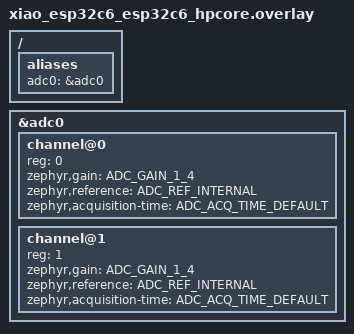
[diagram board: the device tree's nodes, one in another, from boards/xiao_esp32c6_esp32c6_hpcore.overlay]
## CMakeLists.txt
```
# SPDX-FileCopyrightText: 2026 Henrique Freire <hfreire10@hotmail.com>

# SPDX-License-Identifier: MIT

cmake_minimum_required(VERSION 3.20.0)

list(APPEND EXTRA_ZEPHYR_MODULES ${CMAKE_CURRENT_LIST_DIR}/../../modules/wifi_sensing)

find_package(Zephyr REQUIRED HINTS $ENV{ZEPHYR_BASE})
project(collector)

target_sources(app PRIVATE
  src/csi.c
  src/main.c
  # src/sensor.c
)
target_include_directories(app PRIVATE include)
```

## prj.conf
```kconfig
# SPDX-FileCopyrightText: 2026 Henrique Freire <hfreire10@hotmail.com>

# SPDX-License-Identifier: MIT

# Debug
CONFIG_LOG=y
CONFIG_THREAD_NAME=y
CONFIG_STACK_CANARIES=y
CONFIG_STACK_SENTINEL=y
CONFIG_LOG_PROCESS_THREAD_STACK_SIZE=1024

# General
CONFIG_ADC=y
CONFIG_FPU=y
CONFIG_GPIO=y
CONFIG_FLASH=y
CONFIG_EVENTS=y
CONFIG_FLASH_MAP=y
CONFIG_STREAM_FLASH=y
CONFIG_MAIN_STACK_SIZE=4096
CONFIG_HEAP_MEM_POOL_SIZE=102400

# PM
#CONFIG_PM=y
#CONFIG_PM_DEVICE=y

# Networking
CONFIG_NET_UDP=y
CONFIG_NET_IPV4=y
CONFIG_POSIX_API=y
CONFIG_NETWORKING=y
CONFIG_NET_DHCPV4=y
CONFIG_NET_SOCKETS=y

# Try static ESP32 Wi-Fi TX buffers
CONFIG_NET_MAX_CONTEXTS=4
CONFIG_NET_PKT_TX_COUNT=16
CONFIG_NET_BUF_TX_COUNT=48
CONFIG_NET_BUF_DATA_SIZE=512

## WiFi
CONFIG_WIFI=y
CONFIG_WIFI_ESP32=y
CONFIG_NET_L2_WIFI_MGMT=y
CONFIG_WIFI_USAGE_MODE_STA=y
CONFIG_ESP32_WIFI_IRAM_OPT=y
CONFIG_ESP32_WIFI_RX_IRAM_OPT=y
CONFIG_ESP32_WIFI_CSI_ENABLED=y
CONFIG_ESP32_WIFI_STA_RECONNECT=y
```

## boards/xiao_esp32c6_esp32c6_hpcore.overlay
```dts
// SPDX-FileCopyrightText: 2026 Henrique Freire <hfreire10@hotmail.com>

// SPDX-License-Identifier: MIT

/ {
    aliases {
        adc0 = &adc0;
    };
};

&adc0 {
    status = "okay";

    #address-cells = <1>;
	#size-cells = <0>;

    channel@0 {
        reg = <0>;
        zephyr,gain = "ADC_GAIN_1_4";
        zephyr,reference = "ADC_REF_INTERNAL";
        zephyr,acquisition-time = <ADC_ACQ_TIME_DEFAULT>;
    };

    channel@1 {
        reg = <1>;
        zephyr,gain = "ADC_GAIN_1_4";
        zephyr,reference = "ADC_REF_INTERNAL";
        zephyr,acquisition-time = <ADC_ACQ_TIME_DEFAULT>;
    };
};
```

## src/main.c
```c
// SPDX-FileCopyrightText: 2026 Henrique Freire <hfreire10@hotmail.com>

// SPDX-License-Identifier: MIT

#include <zephyr/device.h>
#include <zephyr/devicetree.h>
#include <zephyr/drivers/adc.h>
#include <zephyr/drivers/gpio.h>
#include <zephyr/kernel.h>
#include <zephyr/logging/log.h>
#include <zephyr/net/net_if.h>
#include <zephyr/net/socket.h>
#include <zephyr/net/wifi_mgmt.h>
#include <zephyr/posix/arpa/inet.h>
#include <zephyr/posix/sys/socket.h>
#include <zephyr/posix/unistd.h>

#include <wifi_sensing.h>

#include "collector.h"

LOG_MODULE_REGISTER(collector);

// clang-format off
const struct device *g_adc                = DEVICE_DT_GET(ADC_NODE);
const struct adc_channel_cfg g_adc_cfgs[ADC_CHANNEL_COUNT] = {
    DT_FOREACH_CHILD_SEP(ADC_NODE, ADC_CHANNEL_CFG_DT, (,))
};
// clang-format on

struct in_addr g_ap_addr;
uint8_t g_mac_addr[MAC_ADDR_LEN];

K_SEM_DEFINE(g_sensing_sem, 0, 1);

int udp_socket_open(struct in_addr dest_addr) {
  int sock;
  char ip_str[INET_ADDRSTRLEN];

  struct sockaddr_in server_addr = {
      .sin_family = AF_INET,
      .sin_port   = htons(CONFIG_UDP_PORT),
      .sin_addr   = dest_addr,
  };

  sock = socket(AF_INET, SOCK_DGRAM, IPPROTO_UDP);
  if (sock < 0) {
    LOG_ERR("Failed to create UDP socket: %d", errno);
    return sock;
  }

  if (connect(sock, (struct sockaddr *)&server_addr, sizeof(server_addr)) < 0) {
    LOG_ERR("Failed to connect UDP socket: %d", errno);
    close(sock);
    return -1;
  }

  inet_ntop(AF_INET, &dest_addr, ip_str, sizeof(ip_str));
  LOG_INF("UDP socket registered to %s:%d", ip_str, CONFIG_UDP_PORT);

  return sock;
}

static void adc_init(void) {
  if (!device_is_ready(g_adc)) {
    LOG_ERR("ADC device controller is not ready\n");
  }

  for (size_t i = 0; i < ADC_CHANNEL_COUNT; i++) {
    int err = adc_channel_setup(g_adc, &g_adc_cfgs[i]);

    if (err < 0) {
      LOG_ERR("Could not setup channel #%d: %d\n", g_adc_cfgs[i].channel_id, err);
    }
  }

  // Only setup first ADC sensor (for now)
  g_adc_sequence.channels |= BIT(g_adc_cfgs[0].channel_id);
}

int main(void) {
  LOG_INF("Starting Wi-Fi sensor");

  // Enable environmental sensors and integrated (communication) antenna
  adc_init();
  enable_antenna(INT_ANT);

  net_register(&g_ap_addr);

  wifi_csi_init();
  ap_connect(g_mac_addr);

  return 0;
}
```

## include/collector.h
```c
// SPDX-FileCopyrightText: 2026 Henrique Freire <hfreire10@hotmail.com>

// SPDX-License-Identifier: MIT

#pragma once

#include <stdint.h>

#include <zephyr/devicetree.h>
#include <zephyr/drivers/adc.h>
#include <zephyr/drivers/gpio.h>
#include <zephyr/kernel.h>
#include <zephyr/logging/log.h>

#include <wifi_sensing.h>

#define PACKED __attribute__((packed))

#define ADC_RES           12
#define ADC_NODE          DT_ALIAS(adc0)
#define ADC_CHANNEL_COUNT DT_CHILD_NUM(ADC_NODE)

#define RF_SWITCH_NODE DT_NODELABEL(rf_switch)

typedef enum {
  INT_ANT,
  EXT_ANT,
} antenna_e;

BUILD_ASSERT(DT_NODE_HAS_STATUS_OKAY(ADC_NODE), "ADC controller disabled");

static const struct gpio_dt_spec s_ant_sel = GPIO_DT_SPEC_GET(RF_SWITCH_NODE, select_gpios);

extern const struct device *g_adc;
extern const struct adc_channel_cfg g_adc_cfgs[ADC_CHANNEL_COUNT];

extern struct in_addr g_ap_addr;
extern struct k_sem g_sensing_sem;
extern uint8_t g_mac_addr[MAC_ADDR_LEN];
extern struct adc_sequence g_adc_sequence;

void wifi_csi_init(void);
int udp_socket_open(struct in_addr dest_addr);

static inline void enable_antenna(antenna_e antenna) {
  LOG_MODULE_DECLARE(collector);

  if (!gpio_is_ready_dt(&s_ant_sel)) {
    LOG_ERR("Antenna select GPIO not ready");
    return;
  }

  gpio_pin_set_dt(&s_ant_sel, antenna);
}
```

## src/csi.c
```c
// SPDX-FileCopyrightText: 2026 Henrique Freire <hfreire10@hotmail.com>

// SPDX-License-Identifier: MIT

#include <stdint.h>

#include <zephyr/drivers/gpio.h>
#include <zephyr/kernel.h>
#include <zephyr/logging/log.h>
#include <zephyr/posix/sys/socket.h>

#include <esp_wifi.h>

#include <wifi_sensing.h>

#include "collector.h"

#define CSI_PRIORITY   4
#define CSI_STACK_SIZE 2048

#define QUEUE_SIZE 40
#define MSG_COUNT  (SENSING_WINDOW_SIZE / MAX_MSG_PAYLOAD)

typedef struct {
  unsigned : 32; /**< reserved */
  unsigned : 32; /**< reserved */
  unsigned : 32; /**< reserved */
  unsigned : 32; /**< reserved */
  unsigned : 32; /**< reserved */
#if CONFIG_IDF_TARGET_ESP32S2
  unsigned : 32; /**< reserved */
#elif CONFIG_IDF_TARGET_ESP32S3 || CONFIG_IDF_TARGET_ESP32C3 || CONFIG_IDF_TARGET_ESP32C5 ||       \
    CONFIG_IDF_TARGET_ESP32C6
  unsigned : 16; /**< reserved */
  unsigned fft_gain : 8;
  unsigned agc_gain : 8;
  unsigned : 32; /**< reserved */
#endif
  unsigned : 32; /**< reserved */
#if CONFIG_IDF_TARGET_ESP32S2
  signed : 8;    /**< reserved */
  unsigned : 24; /**< reserved */
#elif CONFIG_IDF_TARGET_ESP32S3 || CONFIG_IDF_TARGET_ESP32C3 || CONFIG_IDF_TARGET_ESP32C5
  unsigned : 32; /**< reserved */
  unsigned : 32; /**< reserved */
  unsigned : 32; /**< reserved */
#endif
  unsigned : 32; /**< reserved */
} PACKED wifi_rx_ctrl_phy_t;

LOG_MODULE_DECLARE(collector);

static void csi_thread(void *, void *, void *);

K_TIMER_DEFINE(s_sensing_timer, NULL, NULL);
K_MSGQ_DEFINE(s_csi_msgq, CSI_DATA_SIZE, QUEUE_SIZE, 4);

K_THREAD_DEFINE(csi_tid, CSI_STACK_SIZE, csi_thread, NULL, NULL, NULL, CSI_PRIORITY, 0, 0);

static void wifi_csi_rx_cb(void *ctx, wifi_csi_info_t *info) {
  wifi_metrics_t frame;

  if (!info || !info->buf) {
    LOG_WRN("<invalid arg> wifi_csi_cb. info: %p %" PRIu16 " %" PRIu16, info->buf, info->len,
            info->rx_seq);
    return;
  }
  const wifi_pkt_rx_ctrl_t *rx_ctrl       = &info->rx_ctrl;
  const wifi_action_frame_t *action_frame = (wifi_action_frame_t *)info->hdr;
  const msg_t *msg                        = (msg_t *)&action_frame->body;

  if (action_frame->frame_ctrl.subtype != ACTION_FRAME_SUBTYPE) {
    LOG_INF("Non action frame, discarding...");
    return;
  }

  if (!IS_BROADCAST_ADDR(action_frame->da)) {
    LOG_INF("Frame from neighboring node, discarding...");
    return;
  }

  if (msg->hdr.id != MSG_ID_PROBE) {
    LOG_INF("Miscellaneous action frame, discarding...");
    return;
  }
  const probe_data_t *probe_msg = (probe_data_t *)&msg->payload.probe;

  memcpy(frame.csi, info->buf, info->len);
  frame.rssi = rx_ctrl->rssi;
  frame.agc  = ((wifi_rx_ctrl_phy_t *)info)->agc_gain;
  frame.seq  = probe_msg->seq;

  LOG_INF("Received CSI frame with size %" PRIu16 ". RSSI: %d dBm. gain: %d, seq: %u", info->len,
          frame.rssi, frame.agc, frame.seq);

  if (!k_msgq_put(&s_csi_msgq, &frame, K_NO_WAIT)) {
    LOG_INF("CSI frame collected [%d dBm]", frame.rssi);
  } else {
    LOG_ERR("Failed to send CSI frame");
  }

  k_sem_give(&g_sensing_sem);
}

void wifi_csi_init(void) {
  const wifi_promiscuous_filter_t filter = {
      .filter_mask = WIFI_PROMIS_FILTER_MASK_MGMT,
  };

  wifi_csi_config_t csi_config = {
      .enable             = true,
      .acquire_csi_legacy = true,
  };

  if (esp_wifi_set_promiscuous(true)) {
    LOG_ERR("Failed to enable promiscuous mode");
    return;
  }

  if (esp_wifi_set_promiscuous_filter(&filter)) {
    LOG_ERR("Failed to set promiscuous filter");
    return;
  }

  if (esp_wifi_set_csi_config(&csi_config)) {
    LOG_ERR("Failed to set CSI config");
    return;
  }

  if (esp_wifi_set_csi_rx_cb(wifi_csi_rx_cb, NULL)) {
    LOG_ERR("Failed to register CSI callback");
    return;
  }

  esp_wifi_set_csi(false);
  LOG_INF("CSI init complete...");
}

static void csi_thread(void *p1 __unused, void *p2 __unused, void *p3 __unused) {
  static uint8_t msg_buf[MSG_COUNT][MSG_HDR_SIZE + MAX_MSG_PAYLOAD * CSI_DATA_SIZE];

  k_event_wait(&g_net_events, NET_READY, false, K_FOREVER);

  int sock = udp_socket_open(g_ap_addr);

  while (true) {
    enable_antenna(EXT_ANT);
    esp_wifi_set_csi(true);

    uint8_t count = 0;
    for (size_t tx = 0; tx < MSG_COUNT; tx++) {
      msg_t *const msg = (msg_t *)msg_buf[tx];
      msg->hdr.id      = MSG_ID_CSI;
      count++;

      csi_data_t *const pkt = (csi_data_t *)&msg->payload.csi;
      pkt->count            = 0;
      for (size_t i = 0; i < MAX_MSG_PAYLOAD; i++) {
        // Reception timeout after one sensing window
        k_timeout_t timeout = i ? K_SECONDS(SENSING_WINDOW_SEC) : K_FOREVER;

        if (k_msgq_get(&s_csi_msgq, &pkt->data[i], timeout)) {
          goto transmit;
        }
        memcpy(pkt->data[i].mac, g_mac_addr, MAC_ADDR_LEN);
        pkt->count++;
      }
    }
  transmit:
    esp_wifi_set_csi(false);
    enable_antenna(INT_ANT);

    // Start timer with a margin of two sensing window
    k_timer_start(&s_sensing_timer, K_SECONDS(SENSING_INTERVAL_SEC - (3 * SENSING_WINDOW_SEC)),
                  K_NO_WAIT);

    for (size_t i = 0; i < count; i++) {
      k_event_wait(&g_net_events, NET_READY, false, K_FOREVER);

      int ret = send(sock, msg_buf[i],
                     MSG_HDR_SIZE + ((msg_t *)msg_buf[i])->payload.csi.count * CSI_DATA_SIZE, 0);

      if (ret < 0) {
        LOG_ERR("Failed to send CSI UDP packet: %d", errno);
      } else {
        LOG_INF("Sent %d bytes to AP", ret);
      }
    }

    // Block until next sensing window
    k_timer_status_sync(&s_sensing_timer);
  }
}
```

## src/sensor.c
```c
// SPDX-FileCopyrightText: 2026 Henrique Freire <hfreire10@hotmail.com>

// SPDX-License-Identifier: MIT

#include <math.h>
#include <stdint.h>

#include <zephyr/devicetree.h>
#include <zephyr/drivers/adc.h>
#include <zephyr/kernel.h>
#include <zephyr/logging/log.h>
#include <zephyr/posix/sys/socket.h>

#include <wifi_sensing.h>

#include "collector.h"

#define SENSOR_PRIORITY   5
#define SENSOR_STACK_SIZE 2048

#define SENSOR_SAMPLES       10
#define SENSOR_INTERVAL_MSEC 1000

#define CHANNEL_VREF(node_id) DT_PROP_OR(node_id, zephyr_vref_mv, 3300)

BUILD_ASSERT(SENSOR_SAMPLES >= 1, "Invalid count of sensor samples");

LOG_MODULE_DECLARE(collector);

// clang-format off
static const uint32_t s_vrefs[] = {
    DT_FOREACH_CHILD_SEP(ADC_NODE, CHANNEL_VREF, (,))
};
// clang-format on

struct adc_sequence g_adc_sequence = {
    .buffer_size = sizeof(uint16_t),
    .resolution  = ADC_RES,
};

static void sensor_thread(void *, void *, void *);

K_THREAD_DEFINE(sensor_tid, SENSOR_STACK_SIZE, sensor_thread, NULL, NULL, NULL, SENSOR_PRIORITY, 0,
                0);

static void sensor_thread(void *p1 __unused, void *p2 __unused, void *p3 __unused) {
  msg_t msg = {
      .hdr.id = MSG_ID_SENSORS,
  };
  sensor_data_t *pkt = &msg.payload.sensor;

  uint16_t adc_reading[SENSOR_SAMPLES];

  k_event_wait(&g_net_events, NET_READY, false, K_FOREVER);
  memcpy(pkt->mac, g_mac_addr, sizeof(pkt->mac));

  int sock = udp_socket_open(g_ap_addr);

  int ret;
  while (true) {
    // Wait for up to 1.5x sensing windows before sensing independently and flag packet on timeout
    pkt->timeout = (k_sem_take(&g_sensing_sem, K_SECONDS(3 * SENSING_INTERVAL_SEC / 2)) != 0);

    uint32_t std  = 0;
    uint32_t mean = 0;
    for (size_t i = 0; i < SENSOR_SAMPLES; i++) {
      g_adc_sequence.buffer = &adc_reading[i];

      ret = adc_read(g_adc, &g_adc_sequence);
      if (ret < 0) {
        LOG_ERR("Could not read sensor: %d", ret);
      }
      uint16_t value = adc_reading[i];

      LOG_DBG("Sensor digital reading %d: %d/%d", i, value, 2 << g_adc_sequence.resolution);

      mean += value;
      std += value * value;

      k_sleep(K_MSEC(SENSOR_INTERVAL_MSEC));
    }

    /*
     * mean = E(x)
     * std² = E{[x - E(x)]²} => E(x²) - E(x)²
     *
     * std_mean = std / sqrt(N)
     */
    std /= SENSOR_SAMPLES;
    mean /= SENSOR_SAMPLES;

    std = (uint32_t)sqrtf(((float)std - mean * mean) / (SENSOR_SAMPLES - 1));

    size_t count           = 0;
    uint32_t filtered_mean = 0;
    for (size_t i = 0; i < SENSOR_SAMPLES; i++) {
      uint16_t value = adc_reading[i];

      if (value >= mean - std && value <= mean + std) {
        filtered_mean += value;
        count++;
      }
    }

    if (count) {
      filtered_mean /= count;
    }

    ret = adc_raw_to_millivolts(s_vrefs[0], g_adc_cfgs[0].gain, g_adc_sequence.resolution,
                                &filtered_mean);
    if (ret < 0) {
      LOG_ERR("Could not convert ADC reading to millivolts: %d", ret);
    }

    pkt->moisture = (uint16_t)filtered_mean;

    ret = send(sock, &msg, MSG_HDR_SIZE + SENSOR_DATA_SIZE, 0);
    if (ret < 0) {
      LOG_ERR("Failed to send sensor UDP packet: %d", errno);
    } else {
      LOG_INF("Sent %d bytes to AP", ret);
    }

    // Ignore any possible signals given while executing thread
    k_sem_reset(&g_sensing_sem);
  }
}
```
